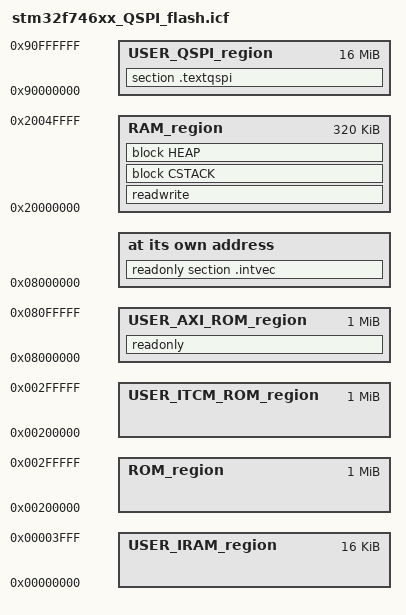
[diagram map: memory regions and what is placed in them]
/*###ICF### Section handled by ICF editor, don't touch! ****/
/*-Editor annotation file-*/
/* IcfEditorFile="$TOOLKIT_DIR$\config\ide\IcfEditor\cortex_v1_0.xml" */
/*-Specials-*/
define symbol __ICFEDIT_intvec_start__ = 0x08000000;
//define symbol __ICFEDIT_intvec_start__ = 0x00200000;
/*-Memory Regions-*/
define symbol __ICFEDIT_region_ROM_start__ = 0x0200000;
define symbol __ICFEDIT_region_ROM_end__   = 0x02FFFFF;
define symbol __ICFEDIT_region_RAM_start__ = 0x20000000;
define symbol __ICFEDIT_region_RAM_end__   = 0x2004FFFF;

/* QSPI 16 MB */
define symbol __USER_region_QSPI_start__ = 0x90000000;
define symbol __USER_region_QSPI_end__   = 0x90FFFFFF;

/* IRAM 16 kB */
define symbol __USER_region_IRAM_start__ = 0x00000000;
define symbol __USER_region_IRAM_end__   = 0x00003FFF;

/* flash AXI 1 MB */
define symbol __USER_region_AXI_start__ = 0x08000000;
define symbol __USER_region_AXI_end__   = 0x080FFFFF;

/* flash ITCM 1 MB */
define symbol __USER_region_ITCM_start__ = 0x00200000;
define symbol __USER_region_ITCM_end__   = 0x002FFFFF;

/*-Sizes-*/
define symbol __ICFEDIT_size_cstack__ = 0x4000;
define symbol __ICFEDIT_size_heap__   = 0x200;
/**** End of ICF editor section. ###ICF###*/


define memory mem with size = 4G;
define region ROM_region      = mem:[from __ICFEDIT_region_ROM_start__   to __ICFEDIT_region_ROM_end__];
define region RAM_region      = mem:[from __ICFEDIT_region_RAM_start__   to __ICFEDIT_region_RAM_end__];

define region USER_AXI_ROM_region		= mem:[from __USER_region_AXI_start__   to __USER_region_AXI_end__];
define region USER_ITCM_ROM_region		= mem:[from __USER_region_ITCM_start__   to __USER_region_ITCM_end__];
define region USER_IRAM_region			= mem:[from __USER_region_IRAM_start__   to __USER_region_IRAM_end__];
define region USER_QSPI_region			= mem:[from __USER_region_QSPI_start__   to __USER_region_QSPI_end__];

define block CSTACK    with alignment = 8, size = __ICFEDIT_size_cstack__   { };
define block HEAP      with alignment = 8, size = __ICFEDIT_size_heap__     { };

initialize by copy {  readwrite  };
do not initialize  { section .noinit };

place at address mem:__ICFEDIT_intvec_start__ { readonly section .intvec };

place in USER_AXI_ROM_region   { readonly };
place in RAM_region   { readwrite,
                        block CSTACK, block HEAP };
place in USER_QSPI_region   { section .textqspi };

                      
